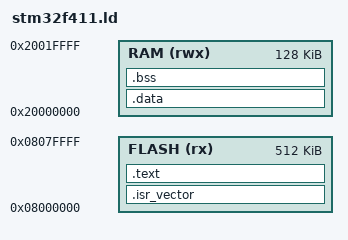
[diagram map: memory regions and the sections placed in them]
/* ld/stm32f411.ld - STM32F411CEU6 Linker Script */
ENTRY(Reset_Handler)

_estack = 0x20020000;  /* top of RAM (128 KB RAM) */

MEMORY
{
  FLASH (rx) : ORIGIN = 0x08000000, LENGTH = 512K
  RAM   (rwx): ORIGIN = 0x20000000, LENGTH = 128K
}

SECTIONS
{
  .isr_vector :
  {
    KEEP(*(.isr_vector))
  } > FLASH

  .text :
  {
    *(.text*)
    *(.rodata*)
  } > FLASH

  .data : AT (ADDR(.text) + SIZEOF(.text))
  {
    _sidata = LOADADDR(.data);
    _sdata = .;
    *(.data*)
    _edata = .;
  } > RAM

  .bss :
  {
    _sbss = .;
    *(.bss*)
    *(COMMON)
    _ebss = .;
  } > RAM

  . = ALIGN(4);
  _end = .;
}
